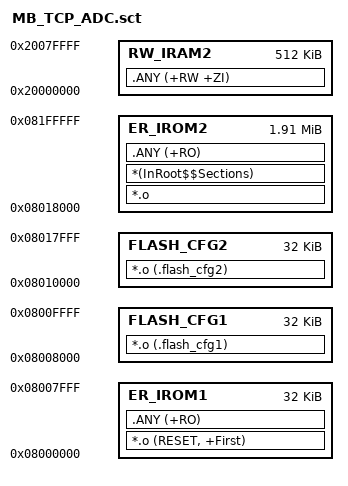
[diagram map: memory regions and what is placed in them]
; *************************************************************
; *** Scatter-Loading Description File generated by uVision ***
; *************************************************************

LR_IROM1 (0x08000000) (0x8000)  {    ; load region size_region
  ER_IROM1 (0x08000000) (0x8000)  {  ; load address = execution address
   *.o (RESET, +First)
   .ANY (+RO)
  }
}

LR_IROM2 	(0x08000000+0x8000+0x8000+0x8000) (0x00200000-0x8000-0x8000-0x8000)  {    ; load region size_region
  ER_IROM2  (0x08000000+0x8000+0x8000+0x8000) (0x00200000-0x8000-0x8000-0x8000)  {  ; load address = execution address
   *.o ;(RESET, +First)
   *(InRoot$$Sections)
   .ANY (+RO)
  }
  RW_IRAM2 0x20000000 0x00080000  {  ; RW data
   .ANY (+RW +ZI)
  }
}

LR_IROM3 (0x08000000+0x8000) 0x00008000  {    ; load region size_region
  FLASH_CFG1 (0x08000000+0x8000) 0x00008000  {  ; load address = execution address
   *.o (.flash_cfg1)
  }
}
LR_IROM4(0x08000000+0x8000+0x8000) 0x00008000  {    ; load region size_region
  FLASH_CFG2 (0x08000000+0x8000+0x8000) 0x00008000  {  ; load address = execution address
   *.o (.flash_cfg2)
  }
}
